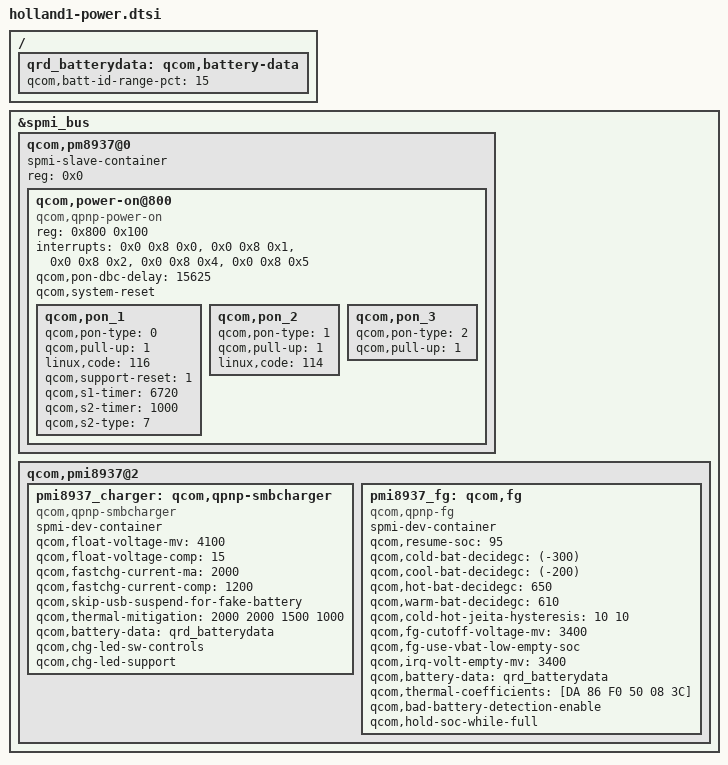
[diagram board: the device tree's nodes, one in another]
/*
 * Copyright (c) 2015-2016, The Linux Foundation. All rights reserved.
 *
 * Copyright (c) 2020, Shubham-Panwar.
 *
 * This program is free software; you can redistribute it and/or modify
 * it under the terms of the GNU General Public License version 2 and
 * only version 2 as published by the Free Software Foundation.
 *
 * This program is distributed in the hope that it will be useful,
 * but WITHOUT ANY WARRANTY; without even the implied warranty of
 * MERCHANTABILITY or FITNESS FOR A PARTICULAR PURPOSE.  See the
 * GNU General Public License for more details.
 */
 
/ {
	/delete-node/ qcom,battery-data;
	qrd_batterydata: qcom,battery-data {
		qcom,batt-id-range-pct = <15>;
		#include "battery/batterydata_Amazon_4V4_4000mAh.dtsi"
	};
};


&spmi_bus {
    
    qcom,pm8937@0 {
		spmi-slave-container;
		reg = <0x0>;
		#address-cells = <1>;
		#size-cells = <1>;
        
        qcom,power-on@800 {
			compatible = "qcom,qpnp-power-on";
			reg = <0x800 0x100>;
			interrupts = <0x0 0x8 0x0>,
				<0x0 0x8 0x1>,
				<0x0 0x8 0x2>,
				<0x0 0x8 0x4>,
				<0x0 0x8 0x5>;
			interrupt-names = "kpdpwr", "resin", "cblpwr",
				"resin-bark", "kpdpwr-resin-bark";
			qcom,pon-dbc-delay = <15625>;
			qcom,system-reset;
			
			/delete-property/ qcom,store-hard-reset-reason;

			qcom,pon_1 {
				qcom,pon-type = <0>;
				qcom,pull-up = <1>;
				linux,code = <116>;
				qcom,support-reset = <1>;
				qcom,s1-timer = <6720>;
				qcom,s2-timer = <1000>;
				qcom,s2-type = <7>;
			};
            
            qcom,pon_2 {
				qcom,pon-type = <1>;
				qcom,pull-up = <1>;
				linux,code = <114>;
			};
			
			qcom,pon_3 {
				qcom,pon-type = <2>;
				qcom,pull-up = <1>;
			};
		};
    };


	qcom,pmi8937@2 {
        pmi8937_charger: qcom,qpnp-smbcharger {
			spmi-dev-container;
			compatible = "qcom,qpnp-smbcharger";
			#address-cells = <1>;
			#size-cells = <1>;            
            qcom,float-voltage-mv = <4100>; /*4400 changed to 4100 in oreo*/
			qcom,float-voltage-comp = <15>;
            qcom,fastchg-current-ma = <2000>;
			qcom,fastchg-current-comp = <1200>;
            qcom,skip-usb-suspend-for-fake-battery;
            qcom,thermal-mitigation = <2000 2000 1500 1000>; /*1200 changed to 1500 in oreo*/
            qcom,battery-data = <&qrd_batterydata>;
			qcom,chg-led-sw-controls;
			qcom,chg-led-support;
			status = "okay";
			/delete-property/ qcom,parallel-usb-min-current-ma;
            /delete-property/ qcom,parallel-usb-9v-min-current-ma;
            /delete-property/ qcom,parallel-allowed-lowering-ma;
        };
        
        pmi8937_fg: qcom,fg {
            spmi-dev-container;
			compatible = "qcom,qpnp-fg";
			#address-cells = <1>;
			#size-cells = <1>;
			qcom,resume-soc = <95>;
			status = "okay";
            qcom,cold-bat-decidegc = <(-300)>;
			qcom,cool-bat-decidegc = <(-200)>;
			qcom,hot-bat-decidegc = <650>;
			qcom,warm-bat-decidegc = <610>;
			qcom,cold-hot-jeita-hysteresis = <10 10>;
            qcom,fg-cutoff-voltage-mv = <3400>;
            qcom,fg-use-vbat-low-empty-soc;
            qcom,irq-volt-empty-mv = <3400>;
			qcom,battery-data = <&qrd_batterydata>;
			qcom,thermal-coefficients = [DA 86 F0 50 08 3C];
    		qcom,bad-battery-detection-enable;
			qcom,hold-soc-while-full;
        };
    };
};
